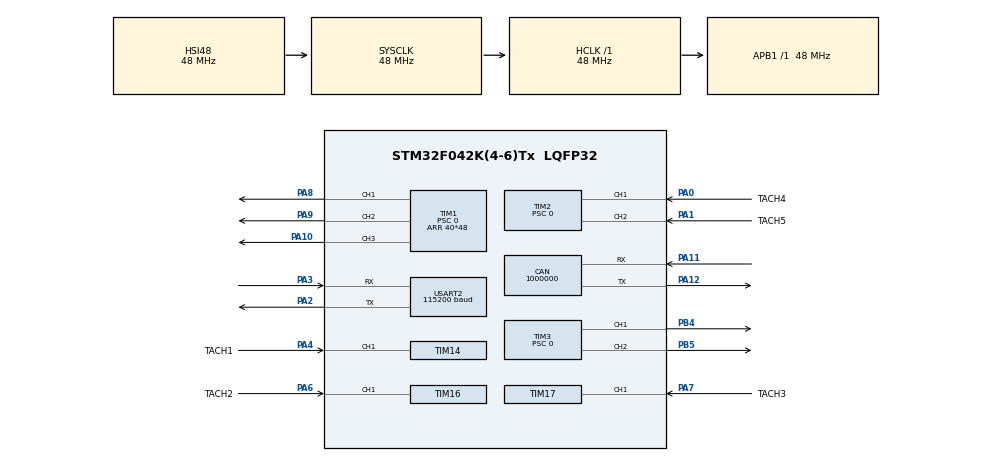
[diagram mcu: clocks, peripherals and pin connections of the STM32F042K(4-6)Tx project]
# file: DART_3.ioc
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CAN.CalculateBaudRate=1000000
CAN.CalculateTimeBit=1000
CAN.CalculateTimeQuantum=333.3333333333333
Mcu.Family=STM32F0
Mcu.Name=STM32F042K(4-6)Tx
Mcu.Package=LQFP32
NVIC.TIM14_IRQn=true\:0\:0\:false\:false\:true\:true\:true\:true
NVIC.TIM1_BRK_UP_TRG_COM_IRQn=true\:0\:0\:false\:false\:true\:true\:true\:true
NVIC.TIM1_CC_IRQn=true\:0\:0\:false\:false\:true\:true\:true\:true
NVIC.TIM2_IRQn=true\:0\:0\:false\:false\:true\:true\:true\:true
NVIC.TIM3_IRQn=true\:0\:0\:false\:false\:true\:true\:true\:true
NVIC.USART2_IRQn=true\:0\:0\:false\:false\:true\:true\:true\:true
PA0.GPIO_Label=TACH4
PA0.Signal=S_TIM2_CH1_ETR
PA1.GPIO_Label=TACH5
PA1.Signal=S_TIM2_CH2
PA10.Signal=S_TIM1_CH3
PA11.Mode=CAN_Activate
PA11.Signal=CAN_RX
PA12.Mode=CAN_Activate
PA12.Signal=CAN_TX
PA13.Mode=Serial_Wire
PA13.Signal=SYS_SWDIO
PA14.Mode=Serial_Wire
PA14.Signal=SYS_SWCLK
PA2.Mode=Asynchronous
PA2.Signal=USART2_TX
PA3.Mode=Asynchronous
PA3.Signal=USART2_RX
PA4.GPIO_Label=TACH1
PA4.Signal=S_TIM14_CH1
PA6.GPIO_Label=TACH2
PA6.Signal=S_TIM16_CH1
PA7.GPIO_Label=TACH3
PA7.Signal=S_TIM17_CH1
PA8.Signal=S_TIM1_CH1
PA9.Signal=S_TIM1_CH2
PB4.Signal=S_TIM3_CH1
PB5.Signal=S_TIM3_CH2
ProjectManager.HeapSize=0x200
ProjectManager.StackSize=0x400
ProjectManager.TargetToolchain=STM32CubeIDE
RCC.AHBFreq_Value=48000000
RCC.APB1Freq_Value=48000000
RCC.APB1TimFreq_Value=48000000
RCC.HCLKFreq_Value=48000000
RCC.SYSCLKFreq_VALUE=48000000
RCC.SYSCLKSource=RCC_SYSCLKSOURCE_HSI48
SH.S_TIM14_CH1.0=TIM14_CH1,Input_Capture1_from_TI1
SH.S_TIM16_CH1.0=TIM16_CH1,Input_Capture1_from_TI1
SH.S_TIM17_CH1.0=TIM17_CH1,Input_Capture1_from_TI1
SH.S_TIM1_CH1.0=TIM1_CH1,PWM Generation1 CH1
SH.S_TIM1_CH2.0=TIM1_CH2,PWM Generation2 CH2
SH.S_TIM1_CH3.0=TIM1_CH3,PWM Generation3 CH3
SH.S_TIM2_CH1_ETR.0=TIM2_CH1,Input_Capture1_from_TI1
SH.S_TIM2_CH2.0=TIM2_CH2,Input_Capture2_from_TI2
SH.S_TIM3_CH1.0=TIM3_CH1,PWM Generation1 CH1
SH.S_TIM3_CH2.0=TIM3_CH2,PWM Generation2 CH2
TIM1.AutoReloadPreload=TIM_AUTORELOAD_PRELOAD_ENABLE
TIM1.Channel-PWM\ Generation1\ CH1=TIM_CHANNEL_1
TIM1.Channel-PWM\ Generation2\ CH2=TIM_CHANNEL_2
TIM1.Channel-PWM\ Generation3\ CH3=TIM_CHANNEL_3
TIM1.Period=40*48
TIM1.Prescaler=0
TIM1.Pulse-PWM\ Generation1\ CH1=25
TIM1.Pulse-PWM\ Generation2\ CH2=25
TIM1.Pulse-PWM\ Generation3\ CH3=25
TIM14.AutoReloadPreload=TIM_AUTORELOAD_PRELOAD_ENABLE
TIM14.Channel=TIM_CHANNEL_1
TIM14.Period=65535
TIM16.Channel=TIM_CHANNEL_1
TIM17.Channel=TIM_CHANNEL_1
TIM2.AutoReloadPreload=TIM_AUTORELOAD_PRELOAD_ENABLE
TIM2.Channel-Input_Capture1_from_TI1=TIM_CHANNEL_1
TIM2.Channel-Input_Capture2_from_TI2=TIM_CHANNEL_2
TIM2.Period=294967295
TIM2.Prescaler=0
TIM3.AutoReloadPreload=TIM_AUTORELOAD_PRELOAD_ENABLE
TIM3.Channel-PWM\ Generation1\ CH1=TIM_CHANNEL_1
TIM3.Channel-PWM\ Generation2\ CH2=TIM_CHANNEL_2
TIM3.Period=40*48
TIM3.Prescaler=0
TIM3.Pulse-PWM\ Generation1\ CH1=25
TIM3.Pulse-PWM\ Generation2\ CH2=25
USART2.BaudRate=115200
USART2.VirtualMode-Asynchronous=VM_ASYNC
VP_TIM14_VS_ClockSourceINT.Mode=Enable_Timer
VP_TIM16_VS_ClockSourceINT.Mode=Enable_Timer
VP_TIM17_VS_ClockSourceINT.Mode=Enable_Timer
VP_TIM1_VS_ClockSourceINT.Mode=Internal
VP_TIM2_VS_ClockSourceINT.Mode=Internal
VP_TIM3_VS_ClockSourceINT.Mode=Internal
board=custom

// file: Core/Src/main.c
/* USER CODE BEGIN Header */
/**
  ******************************************************************************
  * @file           : main.c
  * @brief          : Main program body
  ******************************************************************************
  * @attention
  *
  * Copyright (c) 2024 STMicroelectronics.
  * All rights reserved.
  *
  * This software is licensed under terms that can be found in the LICENSE file
  * in the root directory of this software component.
  * If no LICENSE file comes with this software, it is provided AS-IS.
  *
  ******************************************************************************
  */
/* USER CODE END Header */
#include "main.h"

/* USER CODE BEGIN PD */

// code for calculating frequency

/* USER CODE END PD */

CAN_HandleTypeDef hcan;

TIM_HandleTypeDef htim1;
TIM_HandleTypeDef htim2;
TIM_HandleTypeDef htim3;
TIM_HandleTypeDef htim14;
TIM_HandleTypeDef htim16;
TIM_HandleTypeDef htim17;

UART_HandleTypeDef huart2;

void SystemClock_Config(void);
static void MX_GPIO_Init(void);
static void MX_TIM1_Init(void);
static void MX_TIM2_Init(void);
static void MX_USART2_UART_Init(void);
static void MX_TIM3_Init(void);
static void MX_CAN_Init(void);
static void MX_TIM14_Init(void);
static void MX_TIM16_Init(void);
static void MX_TIM17_Init(void);

int main(void)
{

  /* MCU Configuration--------------------------------------------------------*/

  /* Reset of all peripherals, Initializes the Flash interface and the Systick. */
  HAL_Init();

  /* Configure the system clock */
  SystemClock_Config();

  /* Initialize all configured peripherals */
  MX_GPIO_Init();
  MX_TIM1_Init();
  MX_TIM2_Init();
  MX_USART2_UART_Init();
  MX_TIM3_Init();
  MX_CAN_Init();
  MX_TIM14_Init();
  MX_TIM16_Init();
  MX_TIM17_Init();
  /* USER CODE BEGIN 2 */

  FEB_Init();

  /* USER CODE END 2 */

  /* Infinite loop */
  /* USER CODE BEGIN WHILE */
  while (1)
  {
	  FEB_Main_Loop();

    /* USER CODE END WHILE */

  }
}

void SystemClock_Config(void)
{
  RCC_OscInitTypeDef RCC_OscInitStruct = {0};
  RCC_ClkInitTypeDef RCC_ClkInitStruct = {0};

  /** Initializes the RCC Oscillators according to the specified parameters
  * in the RCC_OscInitTypeDef structure.
  */
  RCC_OscInitStruct.OscillatorType = RCC_OSCILLATORTYPE_HSI48;
  RCC_OscInitStruct.HSI48State = RCC_HSI48_ON;
  RCC_OscInitStruct.PLL.PLLState = RCC_PLL_NONE;
  if (HAL_RCC_OscConfig(&RCC_OscInitStruct) != HAL_OK)
  {
    Error_Handler();
  }

  /** Initializes the CPU, AHB and APB buses clocks
  */
  RCC_ClkInitStruct.ClockType = RCC_CLOCKTYPE_HCLK|RCC_CLOCKTYPE_SYSCLK
                              |RCC_CLOCKTYPE_PCLK1;
  RCC_ClkInitStruct.SYSCLKSource = RCC_SYSCLKSOURCE_HSI48;
  RCC_ClkInitStruct.AHBCLKDivider = RCC_SYSCLK_DIV1;
  RCC_ClkInitStruct.APB1CLKDivider = RCC_HCLK_DIV1;

  if (HAL_RCC_ClockConfig(&RCC_ClkInitStruct, FLASH_LATENCY_1) != HAL_OK)
  {
    Error_Handler();
  }
  HAL_RCC_MCOConfig(RCC_MCO, RCC_MCO1SOURCE_SYSCLK, RCC_MCODIV_1);
}

static void MX_CAN_Init(void)
{

  hcan.Instance = CAN;
  hcan.Init.Prescaler = 16;
  hcan.Init.Mode = CAN_MODE_NORMAL;
  hcan.Init.SyncJumpWidth = CAN_SJW_1TQ;
  hcan.Init.TimeSeg1 = CAN_BS1_1TQ;
  hcan.Init.TimeSeg2 = CAN_BS2_1TQ;
  hcan.Init.TimeTriggeredMode = DISABLE;
  hcan.Init.AutoBusOff = DISABLE;
  hcan.Init.AutoWakeUp = DISABLE;
  hcan.Init.AutoRetransmission = DISABLE;
  hcan.Init.ReceiveFifoLocked = DISABLE;
  hcan.Init.TransmitFifoPriority = DISABLE;
  if (HAL_CAN_Init(&hcan) != HAL_OK)
  {
    Error_Handler();
  }

}

static void MX_TIM1_Init(void)
{

  TIM_ClockConfigTypeDef sClockSourceConfig = {0};
  TIM_MasterConfigTypeDef sMasterConfig = {0};
  TIM_OC_InitTypeDef sConfigOC = {0};
  TIM_BreakDeadTimeConfigTypeDef sBreakDeadTimeConfig = {0};

  htim1.Instance = TIM1;
  htim1.Init.Prescaler = 0;
  htim1.Init.CounterMode = TIM_COUNTERMODE_UP;
  htim1.Init.Period = 40*48;
  htim1.Init.ClockDivision = TIM_CLOCKDIVISION_DIV1;
  htim1.Init.RepetitionCounter = 0;
  htim1.Init.AutoReloadPreload = TIM_AUTORELOAD_PRELOAD_ENABLE;
  if (HAL_TIM_Base_Init(&htim1) != HAL_OK)
  {
    Error_Handler();
  }
  sClockSourceConfig.ClockSource = TIM_CLOCKSOURCE_INTERNAL;
  if (HAL_TIM_ConfigClockSource(&htim1, &sClockSourceConfig) != HAL_OK)
  {
    Error_Handler();
  }
  if (HAL_TIM_PWM_Init(&htim1) != HAL_OK)
  {
    Error_Handler();
  }
  sMasterConfig.MasterOutputTrigger = TIM_TRGO_RESET;
  sMasterConfig.MasterSlaveMode = TIM_MASTERSLAVEMODE_DISABLE;
  if (HAL_TIMEx_MasterConfigSynchronization(&htim1, &sMasterConfig) != HAL_OK)
  {
    Error_Handler();
  }
  sConfigOC.OCMode = TIM_OCMODE_PWM1;
  sConfigOC.Pulse = 25;
  sConfigOC.OCPolarity = TIM_OCPOLARITY_HIGH;
  sConfigOC.OCNPolarity = TIM_OCNPOLARITY_HIGH;
  sConfigOC.OCFastMode = TIM_OCFAST_DISABLE;
  sConfigOC.OCIdleState = TIM_OCIDLESTATE_RESET;
  sConfigOC.OCNIdleState = TIM_OCNIDLESTATE_RESET;
  if (HAL_TIM_PWM_ConfigChannel(&htim1, &sConfigOC, TIM_CHANNEL_1) != HAL_OK)
  {
    Error_Handler();
  }
  if (HAL_TIM_PWM_ConfigChannel(&htim1, &sConfigOC, TIM_CHANNEL_2) != HAL_OK)
  {
    Error_Handler();
  }
  if (HAL_TIM_PWM_ConfigChannel(&htim1, &sConfigOC, TIM_CHANNEL_3) != HAL_OK)
  {
    Error_Handler();
  }
  sBreakDeadTimeConfig.OffStateRunMode = TIM_OSSR_DISABLE;
  sBreakDeadTimeConfig.OffStateIDLEMode = TIM_OSSI_DISABLE;
  sBreakDeadTimeConfig.LockLevel = TIM_LOCKLEVEL_OFF;
  sBreakDeadTimeConfig.DeadTime = 0;
  sBreakDeadTimeConfig.BreakState = TIM_BREAK_DISABLE;
  sBreakDeadTimeConfig.BreakPolarity = TIM_BREAKPOLARITY_HIGH;
  sBreakDeadTimeConfig.AutomaticOutput = TIM_AUTOMATICOUTPUT_DISABLE;
  if (HAL_TIMEx_ConfigBreakDeadTime(&htim1, &sBreakDeadTimeConfig) != HAL_OK)
  {
    Error_Handler();
  }
  HAL_TIM_MspPostInit(&htim1);

}

static void MX_TIM2_Init(void)
{

  TIM_ClockConfigTypeDef sClockSourceConfig = {0};
  TIM_MasterConfigTypeDef sMasterConfig = {0};
  TIM_IC_InitTypeDef sConfigIC = {0};

  htim2.Instance = TIM2;
  htim2.Init.Prescaler = 0;
  htim2.Init.CounterMode = TIM_COUNTERMODE_UP;
  htim2.Init.Period = 294967295;
  htim2.Init.ClockDivision = TIM_CLOCKDIVISION_DIV1;
  htim2.Init.AutoReloadPreload = TIM_AUTORELOAD_PRELOAD_ENABLE;
  if (HAL_TIM_Base_Init(&htim2) != HAL_OK)
  {
    Error_Handler();
  }
  sClockSourceConfig.ClockSource = TIM_CLOCKSOURCE_INTERNAL;
  if (HAL_TIM_ConfigClockSource(&htim2, &sClockSourceConfig) != HAL_OK)
  {
    Error_Handler();
  }
  if (HAL_TIM_IC_Init(&htim2) != HAL_OK)
  {
    Error_Handler();
  }
  sMasterConfig.MasterOutputTrigger = TIM_TRGO_RESET;
  sMasterConfig.MasterSlaveMode = TIM_MASTERSLAVEMODE_DISABLE;
  if (HAL_TIMEx_MasterConfigSynchronization(&htim2, &sMasterConfig) != HAL_OK)
  {
    Error_Handler();
  }
  sConfigIC.ICPolarity = TIM_INPUTCHANNELPOLARITY_RISING;
  sConfigIC.ICSelection = TIM_ICSELECTION_DIRECTTI;
  sConfigIC.ICPrescaler = TIM_ICPSC_DIV1;
  sConfigIC.ICFilter = 0;
  if (HAL_TIM_IC_ConfigChannel(&htim2, &sConfigIC, TIM_CHANNEL_1) != HAL_OK)
  {
    Error_Handler();
  }
  if (HAL_TIM_IC_ConfigChannel(&htim2, &sConfigIC, TIM_CHANNEL_2) != HAL_OK)
  {
    Error_Handler();
  }

}

static void MX_TIM3_Init(void)
{

  TIM_ClockConfigTypeDef sClockSourceConfig = {0};
  TIM_MasterConfigTypeDef sMasterConfig = {0};
  TIM_OC_InitTypeDef sConfigOC = {0};

  htim3.Instance = TIM3;
  htim3.Init.Prescaler = 0;
  htim3.Init.CounterMode = TIM_COUNTERMODE_UP;
  htim3.Init.Period = 40*48;
  htim3.Init.ClockDivision = TIM_CLOCKDIVISION_DIV1;
  htim3.Init.AutoReloadPreload = TIM_AUTORELOAD_PRELOAD_ENABLE;
  if (HAL_TIM_Base_Init(&htim3) != HAL_OK)
  {
    Error_Handler();
  }
  sClockSourceConfig.ClockSource = TIM_CLOCKSOURCE_INTERNAL;
  if (HAL_TIM_ConfigClockSource(&htim3, &sClockSourceConfig) != HAL_OK)
  {
    Error_Handler();
  }
  if (HAL_TIM_PWM_Init(&htim3) != HAL_OK)
  {
    Error_Handler();
  }
  sMasterConfig.MasterOutputTrigger = TIM_TRGO_RESET;
  sMasterConfig.MasterSlaveMode = TIM_MASTERSLAVEMODE_DISABLE;
  if (HAL_TIMEx_MasterConfigSynchronization(&htim3, &sMasterConfig) != HAL_OK)
  {
    Error_Handler();
  }
  sConfigOC.OCMode = TIM_OCMODE_PWM1;
  sConfigOC.Pulse = 25;
  sConfigOC.OCPolarity = TIM_OCPOLARITY_HIGH;
  sConfigOC.OCFastMode = TIM_OCFAST_DISABLE;
  if (HAL_TIM_PWM_ConfigChannel(&htim3, &sConfigOC, TIM_CHANNEL_1) != HAL_OK)
  {
    Error_Handler();
  }
  if (HAL_TIM_PWM_ConfigChannel(&htim3, &sConfigOC, TIM_CHANNEL_2) != HAL_OK)
  {
    Error_Handler();
  }
  HAL_TIM_MspPostInit(&htim3);

}

static void MX_TIM14_Init(void)
{

  TIM_IC_InitTypeDef sConfigIC = {0};

  htim14.Instance = TIM14;
  htim14.Init.Prescaler = 0;
  htim14.Init.CounterMode = TIM_COUNTERMODE_UP;
  htim14.Init.Period = 65535;
  htim14.Init.ClockDivision = TIM_CLOCKDIVISION_DIV1;
  htim14.Init.AutoReloadPreload = TIM_AUTORELOAD_PRELOAD_ENABLE;
  if (HAL_TIM_Base_Init(&htim14) != HAL_OK)
  {
    Error_Handler();
  }
  if (HAL_TIM_IC_Init(&htim14) != HAL_OK)
  {
    Error_Handler();
  }
  sConfigIC.ICPolarity = TIM_INPUTCHANNELPOLARITY_RISING;
  sConfigIC.ICSelection = TIM_ICSELECTION_DIRECTTI;
  sConfigIC.ICPrescaler = TIM_ICPSC_DIV1;
  sConfigIC.ICFilter = 0;
  if (HAL_TIM_IC_ConfigChannel(&htim14, &sConfigIC, TIM_CHANNEL_1) != HAL_OK)
  {
    Error_Handler();
  }

}

static void MX_TIM16_Init(void)
{

  TIM_IC_InitTypeDef sConfigIC = {0};

  htim16.Instance = TIM16;
  htim16.Init.Prescaler = 0;
  htim16.Init.CounterMode = TIM_COUNTERMODE_UP;
  htim16.Init.Period = 65535;
  htim16.Init.ClockDivision = TIM_CLOCKDIVISION_DIV1;
  htim16.Init.RepetitionCounter = 0;
  htim16.Init.AutoReloadPreload = TIM_AUTORELOAD_PRELOAD_DISABLE;
  if (HAL_TIM_Base_Init(&htim16) != HAL_OK)
  {
    Error_Handler();
  }
  if (HAL_TIM_IC_Init(&htim16) != HAL_OK)
  {
    Error_Handler();
  }
  sConfigIC.ICPolarity = TIM_INPUTCHANNELPOLARITY_RISING;
  sConfigIC.ICSelection = TIM_ICSELECTION_DIRECTTI;
  sConfigIC.ICPrescaler = TIM_ICPSC_DIV1;
  sConfigIC.ICFilter = 0;
  if (HAL_TIM_IC_ConfigChannel(&htim16, &sConfigIC, TIM_CHANNEL_1) != HAL_OK)
  {
    Error_Handler();
  }

}

static void MX_TIM17_Init(void)
{

  TIM_IC_InitTypeDef sConfigIC = {0};

  htim17.Instance = TIM17;
  htim17.Init.Prescaler = 0;
  htim17.Init.CounterMode = TIM_COUNTERMODE_UP;
  htim17.Init.Period = 65535;
  htim17.Init.ClockDivision = TIM_CLOCKDIVISION_DIV1;
  htim17.Init.RepetitionCounter = 0;
  htim17.Init.AutoReloadPreload = TIM_AUTORELOAD_PRELOAD_DISABLE;
  if (HAL_TIM_Base_Init(&htim17) != HAL_OK)
  {
    Error_Handler();
  }
  if (HAL_TIM_IC_Init(&htim17) != HAL_OK)
  {
    Error_Handler();
  }
  sConfigIC.ICPolarity = TIM_INPUTCHANNELPOLARITY_RISING;
  sConfigIC.ICSelection = TIM_ICSELECTION_DIRECTTI;
  sConfigIC.ICPrescaler = TIM_ICPSC_DIV1;
  sConfigIC.ICFilter = 0;
  if (HAL_TIM_IC_ConfigChannel(&htim17, &sConfigIC, TIM_CHANNEL_1) != HAL_OK)
  {
    Error_Handler();
  }

}

static void MX_USART2_UART_Init(void)
{

  huart2.Instance = USART2;
  huart2.Init.BaudRate = 115200;
  huart2.Init.WordLength = UART_WORDLENGTH_8B;
  huart2.Init.StopBits = UART_STOPBITS_1;
  huart2.Init.Parity = UART_PARITY_NONE;
  huart2.Init.Mode = UART_MODE_TX_RX;
  huart2.Init.HwFlowCtl = UART_HWCONTROL_NONE;
  huart2.Init.OverSampling = UART_OVERSAMPLING_16;
  huart2.Init.OneBitSampling = UART_ONE_BIT_SAMPLE_DISABLE;
  huart2.AdvancedInit.AdvFeatureInit = UART_ADVFEATURE_NO_INIT;
  if (HAL_UART_Init(&huart2) != HAL_OK)
  {
    Error_Handler();
  }

}

static void MX_GPIO_Init(void)
{

  /* GPIO Ports Clock Enable */
  __HAL_RCC_GPIOA_CLK_ENABLE();
  __HAL_RCC_GPIOB_CLK_ENABLE();

}

/* USER CODE BEGIN 4 */
void HAL_TIM_IC_CaptureCallback(TIM_HandleTypeDef *htim) {
	FEB_Fan_TACH_Callback(htim);
}
/* USER CODE END 4 */

void Error_Handler(void)
{
  __disable_irq();
  while (1)
  {
  }
}
